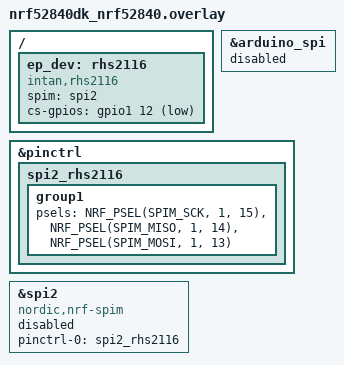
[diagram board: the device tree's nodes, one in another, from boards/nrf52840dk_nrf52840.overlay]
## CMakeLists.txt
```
cmake_minimum_required(VERSION 3.20.0)

# Default `west flash`/`west debug` to the nrfutil runner rather than nrfjprog
# (the legacy nRF Command Line Tools, superseded by nrfutil). Pass `-r <runner>`
# to west to use a different one.
set(BOARD_FLASH_RUNNER nrfutil)

# the RHS2116 driver is an out-of-tree Zephyr module (firmware/modules/rhs2116)
list(APPEND ZEPHYR_EXTRA_MODULES ${CMAKE_CURRENT_SOURCE_DIR}/../modules/rhs2116)

find_package(Zephyr REQUIRED HINTS $ENV{ZEPHYR_BASE})
project(ep_device)

target_include_directories(app PRIVATE src)
target_sources(app PRIVATE
  src/recording.c
  src/stim.c
  src/ble_handler.c
  src/cmd_handler.c
  src/device_info.c
  main/main.c
)

# Zephyr's APP_BUILD_VERSION is only refreshed when the Zephyr repo's index
# changes and never marks uncommitted changes, so generate our own build
# version on every build (see cmake/ep_version.cmake).
set(BUILD_VERSION_H ${CMAKE_CURRENT_BINARY_DIR}/generated/build_version.h)
add_custom_target(ep_build_version
  COMMAND ${CMAKE_COMMAND} -DSRC_DIR=${CMAKE_CURRENT_SOURCE_DIR} -DOUT_FILE=${BUILD_VERSION_H}
          -P ${CMAKE_CURRENT_SOURCE_DIR}/cmake/ep_version.cmake
  BYPRODUCTS ${BUILD_VERSION_H}
)
add_dependencies(app ep_build_version)
target_include_directories(app PRIVATE ${CMAKE_CURRENT_BINARY_DIR}/generated)
```

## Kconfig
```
mainmenu "ep_device"

config EP_DEVICE_HW_REVISION
	int "Hardware (PCB) revision of the ep_device"
	range 0 255
	default 1
	help
	  Reported to the base node by the GET_INFO command. Bump this when
	  building for a new board spin. 0 means a dev kit / breadboard setup.

source "Kconfig.zephyr"
```

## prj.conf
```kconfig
CONFIG_GPIO=y
# the RHS2116 module (firmware/modules/rhs2116) drives SPIM2, TIMER2/3, GPIOTE and
# PPI directly and selects what it needs; NRFX_SPIM2 is only needed for SPIM pinctrl
# support, and is set here because the board's devicetree picks the SPIM
CONFIG_NRFX_SPIM2=y
CONFIG_LOG=y

CONFIG_BT=y
CONFIG_BT_PERIPHERAL=y
CONFIG_BT_ZEPHYR_NUS=y
CONFIG_BT_DEVICE_NAME="mouse"

# Maximum ATT/L2CAP MTU (247 = 251-byte LL data length PDU minus 4-byte
# L2CAP header), backed by matching ACL buffer and controller data length
# sizes so the larger MTU can actually be carried end-to-end.
CONFIG_BT_L2CAP_TX_MTU=247
CONFIG_BT_BUF_ACL_TX_SIZE=251
CONFIG_BT_BUF_ACL_RX_SIZE=251
CONFIG_BT_CTLR_DATA_LENGTH_MAX=251

# Streaming throughput. In Zephyr's controller BT_BUF_ACL_TX_COUNT is also the
# link layer TX queue depth; the default 3 ends each connection event after 3
# packets, leaving the rest of the interval idle. The other counts keep the
# host from becoming the bottleneck instead. recording.c sends with one credit
# per ATT TX buffer (see ble_handler_send_data()).
CONFIG_BT_BUF_ACL_TX_COUNT=16
CONFIG_BT_L2CAP_TX_BUF_COUNT=16
CONFIG_BT_ATT_TX_COUNT=16
CONFIG_BT_CONN_TX_MAX=16

# Connection parameters requested ~5 s after connecting: the default 30-50 ms
# interval (the link test reaches ~1.3 Mbit/s with it), but a 4 s supervision
# timeout like the base node's instead of the default 420 ms, which is easily
# missed under load.
CONFIG_BT_PERIPHERAL_PREF_MIN_INT=24
CONFIG_BT_PERIPHERAL_PREF_MAX_INT=40
CONFIG_BT_PERIPHERAL_PREF_LATENCY=0
CONFIG_BT_PERIPHERAL_PREF_TIMEOUT=400

# report negotiated PHY and data length (logged in ble_handler.c). The USER_*
# options turn the AUTO_* ones off by default, and without AUTO_DATA_LEN_UPDATE
# the host never raises the controller's default TX length from 27 bytes, so
# both are re-enabled explicitly.
CONFIG_BT_USER_PHY_UPDATE=y
CONFIG_BT_USER_DATA_LEN_UPDATE=y
CONFIG_BT_AUTO_PHY_UPDATE=y
CONFIG_BT_AUTO_DATA_LEN_UPDATE=y
```

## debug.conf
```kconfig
# crash hunting: names threads in fault dumps, enables kernel/host asserts and
# gives deferred logging room so a fault dump isn't dropped
#   west build -b <board> ep_device -- -DEXTRA_CONF_FILE="emul.conf;debug.conf"
CONFIG_THREAD_NAME=y
CONFIG_ASSERT=y
CONFIG_LOG_BUFFER_SIZE=4096
```

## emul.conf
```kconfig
# bench testing without the RHS2116 fitted:
#   west build -b <board> ep_device -- -DEXTRA_CONF_FILE=emul.conf
CONFIG_RHS2116_EMUL=y
```

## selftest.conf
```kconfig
# SPI transport self-test at boot (rhs2116_transport_dma_probe() and the stream
# soak in main.c), logged on the console. Takes about a minute.
#   west build -b <board> ep_device -- -DEXTRA_CONF_FILE="emul.conf;debug.conf;selftest.conf"
CONFIG_RHS2116_DMA_PROBE=y
```

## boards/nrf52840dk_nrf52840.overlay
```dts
/*
 * nrf52840dk/nrf52840: the RHS2116 sits on the Arduino header SPI pins
 * (D13/D12/D11 = P1.15/P1.14/P1.13) with CS on D10 (P1.12).
 *
 * the RHS2116 driver drives a SPIM itself (timer/PPI paced streaming). The
 * Arduino header's own bus is spi3, which is avoided because of nRF52840
 * anomaly 198, so spi2 is given the Arduino pins instead and both buses are
 * left disabled for Zephyr's SPI driver.
 */
/ {
    ep_dev: rhs2116 {
        compatible = "intan,rhs2116";
        spim = <&spi2>;
        cs-gpios = <&gpio1 12 GPIO_ACTIVE_LOW>;
    };
};

&arduino_spi {
    status = "disabled";
};

&pinctrl {
    spi2_rhs2116: spi2_rhs2116 {
        group1 {
            psels = <NRF_PSEL(SPIM_SCK, 1, 15)>,
                <NRF_PSEL(SPIM_MISO, 1, 14)>,
                <NRF_PSEL(SPIM_MOSI, 1, 13)>;
        };
    };
};

&spi2 {
    compatible = "nordic,nrf-spim";
    status = "disabled";
    pinctrl-0 = <&spi2_rhs2116>;
    pinctrl-names = "default";
    /delete-property/ pinctrl-1;
};
```

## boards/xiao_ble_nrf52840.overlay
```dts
/*
 * xiao_ble/nrf52840 (base, non-sense):
 * use P0.05 currently for testing with rev1 pcb
 * this corresponds to D5 header on the xiao
 *
 * the RHS2116 driver drives SPIM2 itself (timer/PPI paced streaming), so spi2
 * is left disabled for Zephyr's SPI driver and only its pinctrl (the board's
 * D8/D9/D10 SCK/MISO/MOSI) is used.
 */
/ {
    ep_dev: rhs2116 {
        compatible = "intan,rhs2116";
        spim = <&spi2>;
        cs-gpios = <&gpio0 5 GPIO_ACTIVE_LOW>;
    };
};

&spi2 {
    compatible = "nordic,nrf-spim";
    status = "disabled";
};

// set i2c1 to disabled so that we can use D5 for intan CS line
&i2c1 {
	status = "disabled";
};
```

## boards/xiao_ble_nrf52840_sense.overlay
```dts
/*
 * xiao_ble/nrf52840/sense: the RHS2116 sits on the XIAO expansion header's SPI
 * pins (D8/D9/D10, spi2's pinctrl) with CS on P0.10.
 *
 * the RHS2116 driver drives SPIM2 itself (timer/PPI paced streaming), so spi2
 * is left disabled for Zephyr's SPI driver and only its pinctrl is used.
 */
/ {
    ep_dev: rhs2116 {
        compatible = "intan,rhs2116";
        spim = <&spi2>;
        cs-gpios = <&gpio0 10 GPIO_ACTIVE_LOW>;
    };
};

&spi2 {
    compatible = "nordic,nrf-spim";
    status = "disabled";
};
```

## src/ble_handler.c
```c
#include <zephyr/kernel.h>
#include <zephyr/logging/log.h>

#include <zephyr/bluetooth/bluetooth.h>
#include <zephyr/bluetooth/conn.h>
#include <zephyr/bluetooth/gatt.h>
#include <zephyr/bluetooth/services/nus.h>
#include <zephyr/sys/atomic.h>
#include <zephyr/sys/byteorder.h>

#include "ble_handler.h"

LOG_MODULE_REGISTER(ble_handler, CONFIG_LOG_DEFAULT_LEVEL);

#define DEVICE_NAME     CONFIG_BT_DEVICE_NAME
#define DEVICE_NAME_LEN (sizeof(DEVICE_NAME) - 1)

#define LINK_TEST_STACK     1024
#define LINK_TEST_PRIORITY  8 // below the command thread so STOP is always handled

static const struct ble_handler_cb *app_cb;

// the active connection (ref held), guarded by conn_lock
static struct bt_conn *current_conn;
static struct k_spinlock conn_lock;

static atomic_t link_test_running;
static K_SEM_DEFINE(link_test_sem, 0, 1);

// payload throughput of the last completed link test, 0 if none has run
static atomic_t link_test_last_bps;

/* Credits for data notifications in flight: one per ATT TX buffer, returned by
 * the notify completion callback. Waiting on these instead of retrying
 * bt_gatt_notify() until it stops failing keeps the sender off the host's
 * allocation failure path. Completion callbacks can be skipped when the link
 * drops, so the credits are refilled on every connection. */
#define DATA_TX_CREDITS CONFIG_BT_ATT_TX_COUNT
static K_SEM_DEFINE(data_tx_credits, DATA_TX_CREDITS, DATA_TX_CREDITS);

static const struct bt_data ad[] = {
    BT_DATA_BYTES(BT_DATA_FLAGS, (BT_LE_AD_GENERAL | BT_LE_AD_NO_BREDR)),
    BT_DATA(BT_DATA_NAME_COMPLETE, DEVICE_NAME, DEVICE_NAME_LEN),
};

static const struct bt_data sd[] = {
    BT_DATA_BYTES(BT_DATA_UUID128_ALL, BT_UUID_NUS_SRV_VAL),
};

// -- NEURAL DATA SERVICE --

/* Notify-only characteristic carrying the sample stream (and link test
 * packets), so NUS is left for commands and their replies. The UUIDs are
 * mirrored in base_node/src/ble_central.c; keep the two in sync. */
#define BT_UUID_DATA_SRV_VAL  BT_UUID_128_ENCODE(0xa3c10000, 0x5f2e, 0x4b8a, 0x9d61, 0x7e4f0c2b9a10)
#define BT_UUID_DATA_CHAR_VAL BT_UUID_128_ENCODE(0xa3c10001, 0x5f2e, 0x4b8a, 0x9d61, 0x7e4f0c2b9a10)

static void data_ccc_changed(const struct bt_gatt_attr *attr, uint16_t value) {
    ARG_UNUSED(attr);
    LOG_INF("data notifications %s", value == BT_GATT_CCC_NOTIFY ? "enabled" : "disabled");
}

BT_GATT_SERVICE_DEFINE(data_svc,
    BT_GATT_PRIMARY_SERVICE(BT_UUID_DECLARE_128(BT_UUID_DATA_SRV_VAL)),
    BT_GATT_CHARACTERISTIC(BT_UUID_DECLARE_128(BT_UUID_DATA_CHAR_VAL),
                           BT_GATT_CHRC_NOTIFY, BT_GATT_PERM_NONE, NULL, NULL, NULL),
    BT_GATT_CCC(data_ccc_changed, BT_GATT_PERM_READ | BT_GATT_PERM_WRITE),
    BT_GATT_CUD("Neural Data", BT_GATT_PERM_READ),
);

// the characteristic declaration; bt_gatt_notify() resolves its value handle
#define DATA_CHAR_ATTR (&data_svc.attrs[1])

static void connected(struct bt_conn *conn, uint8_t err) {
    if (err) {
        LOG_ERR("BLE connection failed: %u", err);
        return;
    }
    LOG_INF("BLE connected");

    k_spinlock_key_t key = k_spin_lock(&conn_lock);
    current_conn = bt_conn_ref(conn);
    k_spin_unlock(&conn_lock, key);

    k_sem_reset(&data_tx_credits);
    for (int i = 0; i < DATA_TX_CREDITS; i++) {
        k_sem_give(&data_tx_credits);
    }

    if (app_cb && app_cb->connected) {
        app_cb->connected();
    }
}

static void adv_restart_work_handler(struct k_work *work) {
    ARG_UNUSED(work);

    int ret = bt_le_adv_start(BT_LE_ADV_CONN_ONE_TIME, ad, ARRAY_SIZE(ad), sd, ARRAY_SIZE(sd));
    if (ret) {
        LOG_ERR("Advertising failed to restart: %d", ret);
    } else {
        LOG_INF("BLE advertising restarted");
    }
}

static K_WORK_DEFINE(adv_restart_work, adv_restart_work_handler);

static void disconnected(struct bt_conn *conn, uint8_t reason) {
    LOG_INF("BLE disconnected, reason: %u", reason);

    k_spinlock_key_t key = k_spin_lock(&conn_lock);
    if (current_conn == conn) {
        bt_conn_unref(current_conn);
        current_conn = NULL;
    }
    k_spin_unlock(&conn_lock, key);

    ble_handler_link_test_stop();

    if (app_cb && app_cb->disconnected) {
        app_cb->disconnected();
    }

    // Defer to the system workqueue: the connection object isn't fully
    // released until this callback returns, so advertising can't restart here.
    k_work_submit(&adv_restart_work);
}

// negotiated link parameters, logged to check what the streaming rate can rely on
static void le_param_updated(struct bt_conn *conn, uint16_t interval, uint16_t latency,
                             uint16_t timeout) {
    ARG_UNUSED(conn);
    LOG_INF("conn params: interval %u.%02u ms, latency %u, timeout %u ms",
            interval * 125 / 100, interval * 125 % 100, latency, timeout * 10);
}

static void le_phy_updated(struct bt_conn *conn, struct bt_conn_le_phy_info *param) {
    ARG_UNUSED(conn);
    LOG_INF("PHY: tx %s, rx %s", param->tx_phy == BT_GAP_LE_PHY_2M ? "2M" : "1M/coded",
            param->rx_phy == BT_GAP_LE_PHY_2M ? "2M" : "1M/coded");
}

static void le_data_len_updated(struct bt_conn *conn, struct bt_conn_le_data_len_info *info) {
    ARG_UNUSED(conn);
    LOG_INF("data length: tx %u B / %u us, rx %u B / %u us", info->tx_max_len,
            info->tx_max_time, info->rx_max_len, info->rx_max_time);
}

BT_CONN_CB_DEFINE(conn_callbacks) = {
    .connected = connected,
    .disconnected = disconnected,
    .le_param_updated = le_param_updated,
    .le_phy_updated = le_phy_updated,
    .le_data_len_updated = le_data_len_updated,
};

static void nus_notif_enabled(bool enabled, void *ctx) {
    ARG_UNUSED(ctx);
    LOG_INF("NUS notifications %s", enabled ? "enabled" : "disabled");
}

static void nus_received(struct bt_conn *conn, const void *data, uint16_t len, void *ctx) {
    ARG_UNUSED(conn);
    ARG_UNUSED(ctx);
    LOG_HEXDUMP_DBG(data, len, "NUS RX");

    if (app_cb && app_cb->received) {
        app_cb->received(data, len);
    }
}

static struct bt_nus_cb nus_callbacks = {
    .notif_enabled = nus_notif_enabled,
    .received = nus_received,
};

int ble_handler_init(const struct ble_handler_cb *cb) {
    app_cb = cb;

    int ret = bt_nus_cb_register(&nus_callbacks, NULL);
    if (ret) {
        LOG_ERR("Failed to register NUS callbacks: %d", ret);
        return ret;
    }

    ret = bt_enable(NULL);
    if (ret) {
        LOG_ERR("Bluetooth init failed: %d", ret);
        return ret;
    }

    ret = bt_le_adv_start(BT_LE_ADV_CONN_ONE_TIME, ad, ARRAY_SIZE(ad), sd, ARRAY_SIZE(sd));
    if (ret) {
        LOG_ERR("Advertising failed to start: %d", ret);
        return ret;
    }

    LOG_INF("BLE advertising started as \"%s\"", DEVICE_NAME);
    return 0;
}

int ble_handler_send(const void *data, uint16_t len) {
    return bt_nus_send(NULL, data, len);
}

// returns a new ref to the active connection, or NULL; caller must bt_conn_unref()
static struct bt_conn *get_conn(void) {
    struct bt_conn *conn = NULL;

    k_spinlock_key_t key = k_spin_lock(&conn_lock);
    if (current_conn) {
        conn = bt_conn_ref(current_conn);
    }
    k_spin_unlock(&conn_lock, key);

    return conn;
}

static void data_sent(struct bt_conn *conn, void *user_data) {
    ARG_UNUSED(conn);
    ARG_UNUSED(user_data);
    k_sem_give(&data_tx_credits);
}

int ble_handler_send_data(const void *data, uint16_t len, k_timeout_t timeout) {
    if (k_sem_take(&data_tx_credits, timeout) != 0) {
        return -EAGAIN;
    }

    struct bt_conn *conn = get_conn();
    if (conn == NULL) {
        k_sem_give(&data_tx_credits);
        return -ENOTCONN;
    }

    struct bt_gatt_notify_params params = {
        .attr = DATA_CHAR_ATTR,
        .data = data,
        .len = len,
        .func = data_sent,
    };
    int ret = bt_gatt_notify_cb(conn, &params);
    if (ret) {
        k_sem_give(&data_tx_credits);
    }
    bt_conn_unref(conn);
    return ret;
}

uint16_t ble_handler_data_payload_max(void) {
    struct bt_conn *conn = get_conn();
    if (conn == NULL) {
        return 0;
    }
    uint16_t len = bt_gatt_get_mtu(conn) - 3; // ATT notify header
    bt_conn_unref(conn);
    return MIN(len, CONFIG_BT_L2CAP_TX_MTU - 3);
}

uint32_t ble_handler_link_test_last_bps(void) {
    return (uint32_t)atomic_get(&link_test_last_bps);
}

// -- BLE LINK TEST --

/* Sends full-size data notifications back to back. Each packet starts with a
 * little-endian u32 sequence number (so the receiver can count drops) followed
 * by a fixed byte pattern. bt_gatt_notify() blocks while the TX buffers are full,
 * so this runs at whatever rate the link can sustain. */
static void link_test_thread(void *p1, void *p2, void *p3) {
    ARG_UNUSED(p1);
    ARG_UNUSED(p2);
    ARG_UNUSED(p3);

    static uint8_t buf[CONFIG_BT_L2CAP_TX_MTU - 3]; // ATT MTU minus the notify header

    for (size_t i = 0; i < sizeof(buf); i++) {
        buf[i] = (uint8_t)i;
    }

    while (1) {
        k_sem_take(&link_test_sem, K_FOREVER);

        struct bt_conn *conn = get_conn();
        if (conn == NULL) {
            LOG_WRN("link test: not connected");
            atomic_clear(&link_test_running);
            continue;
        }

        // the negotiated MTU may be smaller than the configured maximum
        uint16_t len = MIN(bt_gatt_get_mtu(conn) - 3, sizeof(buf));
        uint32_t seq = 0;
        uint64_t bytes = 0;
        int64_t start = k_uptime_get();

        LOG_INF("link test started, %u byte packets", len);

        while (atomic_get(&link_test_running)) {
            sys_put_le32(seq, buf);

            int ret = bt_gatt_notify(conn, DATA_CHAR_ATTR, buf, len);
            if (ret == -EAGAIN || ret == -ENOMEM) {
                k_yield();
                continue;
            }
            if (ret) {
                /* e.g. -ENOTCONN on disconnect (the base restarts the test on
                 * reconnect) or -EINVAL if the peer isn't subscribed */
                LOG_ERR("link test: send failed: %d", ret);
                atomic_clear(&link_test_running);
                break;
            }
            seq++;
            bytes += len;
        }

        /* Don't clear link_test_running here: a stop followed quickly by a new
         * start would otherwise be undone. A pending start re-runs the loop via
         * link_test_sem. */
        bt_conn_unref(conn);

        int64_t elapsed_ms = MAX(k_uptime_get() - start, 1);
        atomic_set(&link_test_last_bps, (atomic_val_t)(bytes * 1000 / elapsed_ms));
        LOG_INF("link test stopped: %u packets, %llu bytes in %lld ms (%llu B/s)",
                seq, bytes, elapsed_ms, bytes * 1000 / elapsed_ms);
    }
}

K_THREAD_DEFINE(link_test_tid, LINK_TEST_STACK, link_test_thread, NULL, NULL, NULL,
                LINK_TEST_PRIORITY, 0, 0);

int ble_handler_link_test_start(void) {
    if (atomic_set(&link_test_running, 1)) {
        return -EALREADY;
    }
    k_sem_give(&link_test_sem);
    return 0;
}

void ble_handler_link_test_stop(void) {
    atomic_clear(&link_test_running);
}
```

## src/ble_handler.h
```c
#ifndef BLE_HANDLER_H
#define BLE_HANDLER_H

#include <stdint.h>

#include <zephyr/kernel.h>

/* Application hooks invoked from the BLE stack's context on link changes. */
struct ble_handler_cb {
    void (*connected)(void);
    void (*disconnected)(void);
    /* Data written by the peer to NUS RX. Runs on the BLE RX thread, so it
     * must not block. */
    void (*received)(const uint8_t *data, uint16_t len);
};

/* Registers NUS callbacks, enables Bluetooth and starts advertising.
 * cb may be NULL; the pointed-to struct must outlive the BLE stack. */
int ble_handler_init(const struct ble_handler_cb *cb);

/* Sends data over NUS to all connected peers; used for command replies.
 * Returns bt_nus_send()'s result (-ENOTCONN when nothing is connected, -EAGAIN
 * when TX buffers are full). */
int ble_handler_send(const void *data, uint16_t len);

/* Notifies data on the neural data characteristic to the connected peer.
 * Waits up to timeout for one of the CONFIG_BT_ATT_TX_COUNT notification
 * credits, which come back as the controller finishes sending earlier ones.
 * Returns -EAGAIN if none came back in time, -ENOTCONN when not connected,
 * -EINVAL if the peer isn't subscribed, or another bt_gatt_notify_cb() error. */
int ble_handler_send_data(const void *data, uint16_t len, k_timeout_t timeout);

/* Largest notification payload on the data characteristic for the current
 * connection (negotiated ATT MTU minus the notify header), or 0 if not connected. */
uint16_t ble_handler_data_payload_max(void);

/* Payload bytes/s achieved by the last completed link test, 0 if none has run. */
uint32_t ble_handler_link_test_last_bps(void);

/* Starts streaming full-size data characteristic packets of dummy data (u32 LE sequence number
 * then a byte pattern) as fast as the link allows, on its own thread.
 * Returns -EALREADY if a test is already running. */
int ble_handler_link_test_start(void);

/* Stops the link test; also called automatically on disconnect. */
void ble_handler_link_test_stop(void);

#endif /* BLE_HANDLER_H */
```

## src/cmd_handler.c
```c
#include <errno.h>
#include <string.h>

#include <zephyr/device.h>
#include <zephyr/devicetree.h>
#include <zephyr/kernel.h>
#include <zephyr/logging/log.h>
#include <zephyr/sys/byteorder.h>
#include <zephyr/sys/util.h>

#include "ble_handler.h"
#include "cmd_handler.h"
#include "device_info.h"
#include "recording.h"
#include "stim.h"

LOG_MODULE_REGISTER(cmd_handler, CONFIG_LOG_DEFAULT_LEVEL);

#define CMD_QUEUE_DEPTH      4
#define CMD_THREAD_STACK     2048
#define CMD_THREAD_PRIORITY  7

struct cmd_packet {
    uint16_t len;
    uint8_t data[CMD_MAX_LEN];
};

K_MSGQ_DEFINE(cmd_msgq, sizeof(struct cmd_packet), CMD_QUEUE_DEPTH, 4);

/* Handlers run on the command thread (not the BLE stack), so they may block,
 * e.g. on SPI transfers to the RHS2116. Return 0 on success or a negative errno. */
typedef int (*cmd_fn_t)(const uint8_t *payload, uint16_t len);

struct cmd_entry {
    uint8_t opcode;
    const char *name;
    uint16_t min_len; /* payload bytes, excluding the opcode */
    uint16_t max_len;
    cmd_fn_t fn;
};

static const struct device *const rhs2116_dev = DEVICE_DT_GET(DT_NODELABEL(ep_dev));

// -- COMMAND HANDLERS --

// sends [opcode][status][body...] over NUS
static int reply(uint8_t opcode, int status, const uint8_t *body, uint16_t body_len) {
    uint8_t buf[2 + 48];

    __ASSERT_NO_MSG(body_len <= sizeof(buf) - 2);
    buf[0] = opcode;
    buf[1] = (uint8_t)(int8_t)status;
    if (body_len) {
        memcpy(&buf[2], body, body_len);
    }
    (void)ble_handler_send(buf, body_len + 2);
    return status;
}

static int handle_ping(const uint8_t *payload, uint16_t len) {
    ARG_UNUSED(payload);
    ARG_UNUSED(len);
    LOG_INF("ping");
    return 0;
}

static int handle_get_info(const uint8_t *payload, uint16_t len) {
    ARG_UNUSED(payload);
    ARG_UNUSED(len);

    uint8_t reply[CMD_MAX_LEN];
    reply[0] = CMD_GET_INFO;

    int ret = device_info_encode(&reply[1], sizeof(reply) - 1);
    if (ret < 0) {
        return ret;
    }
    return ble_handler_send(reply, ret + 1);
}

static int handle_start_recording(const uint8_t *payload, uint16_t len) {
    ARG_UNUSED(len);

    struct rec_params params = {
        .chan_mask = sys_get_le16(&payload[0]),
        .rate_hz = sys_get_le32(&payload[2]),
        .bits = payload[6],
    };
    struct rec_info info;

    int ret = recording_start(rhs2116_dev, &params, &info);

    uint8_t body[22];
    body[0] = info.reject;
    sys_put_le32(info.rate_mhz, &body[1]);
    sys_put_le16((uint16_t)info.slot_ticks, &body[5]);
    body[7] = info.slots_per_frame;
    body[8] = info.frames_per_packet;
    sys_put_le32(info.required_bps, &body[9]);
    sys_put_le32(info.link_bps, &body[13]);
    sys_put_le32(info.max_rate_hz, &body[17]);
    return reply(CMD_START_RECORDING, ret, body, 21);
}

static int handle_stop_recording(const uint8_t *payload, uint16_t len) {
    ARG_UNUSED(payload);
    ARG_UNUSED(len);

    // stimulation is timed by the stream, so it has to wind down first
    stim_stop();
    recording_stop();
    return reply(CMD_STOP_RECORDING, 0, NULL, 0);
}

static int handle_start_stimulation(const uint8_t *payload, uint16_t len) {
    ARG_UNUSED(payload);
    ARG_UNUSED(len);

    enum stim_reject why;
    int ret = stim_start(rhs2116_dev, &why);
    uint8_t body[1] = { why };
    return reply(CMD_START_STIMULATION, ret, body, sizeof(body));
}

static int handle_stop_stimulation(const uint8_t *payload, uint16_t len) {
    ARG_UNUSED(payload);
    ARG_UNUSED(len);

    stim_stop();
    return reply(CMD_STOP_STIMULATION, 0, NULL, 0);
}

static int handle_stim_load_biphasic(const uint8_t *payload, uint16_t len) {
    ARG_UNUSED(len);

    struct stim_biphasic b = {
        .chan_mask = sys_get_le16(&payload[0]),
        .neg_mag = payload[2],
        .pos_mag = payload[3],
        .flags = payload[4],
        .phase1_us = sys_get_le16(&payload[5]),
        .interphase_us = sys_get_le16(&payload[7]),
        .phase2_us = sys_get_le16(&payload[9]),
        .recovery_us = sys_get_le16(&payload[11]),
        .period_us = sys_get_le32(&payload[13]),
        .count = sys_get_le16(&payload[17]),
    };
    struct stim_biphasic_frames f = {0};
    enum stim_reject why;

    int ret = stim_load_biphasic(&b, &f, &why);

    uint8_t body[13];
    body[0] = why;
    sys_put_le16(f.phase1, &body[1]);
    sys_put_le16(f.interphase, &body[3]);
    sys_put_le16(f.phase2, &body[5]);
    sys_put_le16(f.recovery, &body[7]);
    sys_put_le32(f.period, &body[9]);
    return reply(CMD_STIM_LOAD_BIPHASIC, ret, body, sizeof(body));
}

#define STIM_EVENTS_HDR_LEN 14

static int handle_stim_load_events(const uint8_t *payload, uint16_t len) {
    struct stim_program p = {
        .chan_mask = sys_get_le16(&payload[0]),
        .neg_mag = payload[2],
        .pos_mag = payload[3],
        .flags = payload[4],
        .period_frames = sys_get_le32(&payload[5]),
        .count = sys_get_le16(&payload[9]),
        .recovery_frames = sys_get_le16(&payload[11]),
        .n_events = payload[13],
    };
    enum stim_reject why = STIM_BAD_EVENTS;
    int ret = -EINVAL;

    if (p.n_events <= STIM_MAX_EVENTS &&
        len == STIM_EVENTS_HDR_LEN + p.n_events * CMD_STIM_EVENT_LEN) {
        const uint8_t *e = &payload[STIM_EVENTS_HDR_LEN];
        for (uint8_t i = 0; i < p.n_events; i++, e += CMD_STIM_EVENT_LEN) {
            p.events[i] = (struct stim_event){
                .frame = sys_get_le32(&e[0]),
                .on = sys_get_le16(&e[4]),
                .pol = sys_get_le16(&e[6]),
                .n_extra = e[8],
                .extra = {
                    { .reg = e[9], .val = sys_get_le16(&e[10]) },
                    { .reg = e[12], .val = sys_get_le16(&e[13]) },
                },
            };
        }
        ret = stim_load_program(&p, &why);
    }

    uint8_t body[1] = { why };
    return reply(CMD_STIM_LOAD_EVENTS, ret, body, sizeof(body));
}

static int handle_get_recording_stats(const uint8_t *payload, uint16_t len) {
    ARG_UNUSED(payload);
    ARG_UNUSED(len);

    struct rec_stats st;
    recording_get_stats(&st);

    uint8_t body[38];
    body[0] = recording_active();
    body[1] = stim_running();
    sys_put_le32(st.stream.frames, &body[2]);
    sys_put_le32(st.stream.blocks, &body[6]);
    sys_put_le32(st.stream.spi_errors, &body[10]);
    sys_put_le32(st.stream.compliance_events, &body[14]);
    sys_put_le32(st.stream.transport.rewinds, &body[18]);
    sys_put_le32(st.stream.transport.late_rewinds, &body[22]);
    sys_put_le32(st.stream.transport.max_guard_used, &body[26]);
    sys_put_le32(st.packets_sent, &body[30]);
    sys_put_le32(st.packets_dropped, &body[34]);
    return reply(CMD_GET_RECORDING_STATS, 0, body, sizeof(body));
}

// payload: u16 channel mask, bit n == RHS2116 channel n
static int handle_set_electrode_mask(const uint8_t *payload, uint16_t len) {
    ARG_UNUSED(len);
    uint16_t mask = sys_get_le16(payload);

    LOG_INF("electrode mask 0x%04x", mask);
    // TODO: store the mask and apply it to the recording/stim channel selection
    return 0;
}

static int handle_start_ble_link_test(const uint8_t *payload, uint16_t len) {
    ARG_UNUSED(payload);
    ARG_UNUSED(len);
    return ble_handler_link_test_start();
}

static int handle_stop_ble_link_test(const uint8_t *payload, uint16_t len) {
    ARG_UNUSED(payload);
    ARG_UNUSED(len);
    ble_handler_link_test_stop();
    return 0;
}

// -- DISPATCH --

/* Add new commands here: an opcode in cmd_handler.h, a handler above, and an
 * entry below giving the accepted payload length range. */
static const struct cmd_entry cmd_table[] = {
    { CMD_PING,               "PING",               0, 0, handle_ping },
    { CMD_GET_INFO,           "GET_INFO",           0, 0, handle_get_info },
    { CMD_START_RECORDING,    "START_RECORDING",    7, 7, handle_start_recording },
    { CMD_STOP_RECORDING,     "STOP_RECORDING",     0, 0, handle_stop_recording },
    { CMD_START_STIMULATION,  "START_STIMULATION",  0, 0, handle_start_stimulation },
    { CMD_STOP_STIMULATION,   "STOP_STIMULATION",   0, 0, handle_stop_stimulation },
    { CMD_STIM_LOAD_BIPHASIC, "STIM_LOAD_BIPHASIC", 19, 19, handle_stim_load_biphasic },
    { CMD_STIM_LOAD_EVENTS,   "STIM_LOAD_EVENTS",   STIM_EVENTS_HDR_LEN,
      STIM_EVENTS_HDR_LEN + STIM_MAX_EVENTS * CMD_STIM_EVENT_LEN, handle_stim_load_events },
    { CMD_GET_RECORDING_STATS, "GET_RECORDING_STATS", 0, 0, handle_get_recording_stats },
    { CMD_SET_ELECTRODE_MASK, "SET_ELECTRODE_MASK", 2, 2, handle_set_electrode_mask },
    { CMD_START_BLE_LINK_TEST, "START_BLE_LINK_TEST", 0, 0, handle_start_ble_link_test },
    { CMD_STOP_BLE_LINK_TEST,  "STOP_BLE_LINK_TEST",  0, 0, handle_stop_ble_link_test },
};

static const struct cmd_entry *find_cmd(uint8_t opcode) {
    for (size_t i = 0; i < ARRAY_SIZE(cmd_table); i++) {
        if (cmd_table[i].opcode == opcode) {
            return &cmd_table[i];
        }
    }
    return NULL;
}

static void dispatch(const struct cmd_packet *pkt) {
    uint8_t opcode = pkt->data[0];
    const uint8_t *payload = &pkt->data[1];
    uint16_t payload_len = pkt->len - 1;

    const struct cmd_entry *cmd = find_cmd(opcode);
    if (cmd == NULL) {
        LOG_WRN("unknown opcode 0x%02x (%u byte payload)", opcode, payload_len);
        return;
    }

    if (payload_len < cmd->min_len || payload_len > cmd->max_len) {
        LOG_WRN("%s: bad payload length %u (expected %u..%u)",
                cmd->name, payload_len, cmd->min_len, cmd->max_len);
        return;
    }

    int ret = cmd->fn(payload, payload_len);
    if (ret < 0) {
        LOG_ERR("%s failed: %d", cmd->name, ret);
    } else {
        LOG_DBG("%s ok", cmd->name);
    }
}

static void cmd_thread(void *p1, void *p2, void *p3) {
    ARG_UNUSED(p1);
    ARG_UNUSED(p2);
    ARG_UNUSED(p3);

    struct cmd_packet pkt;

    while (1) {
        k_msgq_get(&cmd_msgq, &pkt, K_FOREVER);
        dispatch(&pkt);
    }
}

K_THREAD_DEFINE(cmd_tid, CMD_THREAD_STACK, cmd_thread, NULL, NULL, NULL,
                CMD_THREAD_PRIORITY, 0, 0);

int cmd_handler_submit(const uint8_t *data, uint16_t len) {
    if (len == 0 || len > CMD_MAX_LEN) {
        LOG_WRN("dropping command of length %u", len);
        return -EINVAL;
    }

    struct cmd_packet pkt = { .len = len };
    memcpy(pkt.data, data, len);

    // never block here: this is called from the BLE RX thread
    int ret = k_msgq_put(&cmd_msgq, &pkt, K_NO_WAIT);
    if (ret) {
        LOG_WRN("command queue full, dropping opcode 0x%02x", data[0]);
        return -ENOMEM;
    }
    return 0;
}

void cmd_handler_stop_all(void) {
    uint8_t stop = CMD_STOP_RECORDING;
    (void)cmd_handler_submit(&stop, 1);
}
```

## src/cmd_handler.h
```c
#ifndef CMD_HANDLER_H
#define CMD_HANDLER_H

#include <stdint.h>

/*
 * Command packet format (base node -> ep_device, over NUS RX):
 *
 *   byte 0      opcode   (enum cmd_opcode)
 *   byte 1..n   payload  (opcode specific, multi-byte fields little-endian)
 *
 * One NUS write carries exactly one command. The payload length is whatever
 * follows the opcode, and is checked against the opcode's table entry in
 * cmd_handler.c before the handler runs.
 *
 * Commands that return data reply over NUS TX with the same layout:
 * [opcode of the command][payload...].
 */

/* Largest command accepted: one ATT MTU (247) minus the 3-byte ATT header. */
#define CMD_MAX_LEN 244

enum cmd_opcode {
    CMD_PING               = 0x01,
    CMD_GET_INFO           = 0x02, /* replies with device_info.h's payload */

    /* recording / stimulation control, payloads and replies below */
    CMD_START_RECORDING    = 0x10,
    CMD_STOP_RECORDING     = 0x11,
    CMD_START_STIMULATION  = 0x12,
    CMD_STOP_STIMULATION   = 0x13,
    CMD_STIM_LOAD_BIPHASIC = 0x14,
    CMD_STIM_LOAD_EVENTS   = 0x15,
    CMD_GET_RECORDING_STATS = 0x16,

    /* electrode setup / parameters */
    CMD_SET_ELECTRODE_MASK = 0x20,

    /* diagnostics */
    CMD_START_BLE_LINK_TEST = 0x30,
    CMD_STOP_BLE_LINK_TEST  = 0x31,
};

/*
 * Recording / stimulation payloads (all little-endian). Every one of these
 * commands replies [opcode][status s8 (0 or -errno)]... as listed.
 *
 * START_RECORDING   payload: chan_mask u16, rate_hz u32, bits u8
 *                   reply:   status, reject u8 (enum rec_reject), rate_mhz u32,
 *                            slot_ticks u16, slots_per_frame u8, frames_per_packet u8,
 *                            required_bps u32, link_bps u32, max_rate_hz u32
 * STOP_RECORDING    reply:   status (also stops any stimulation first)
 * START_STIMULATION reply:   status, reject u8 (enum stim_reject)
 * STOP_STIMULATION  reply:   status
 * STIM_LOAD_BIPHASIC payload: chan_mask u16, neg_mag u8, pos_mag u8, flags u8,
 *                            phase1_us u16, interphase_us u16, phase2_us u16,
 *                            recovery_us u16, period_us u32, count u16
 *                   reply:   status, reject u8, phase1 u16, interphase u16, phase2 u16,
 *                            recovery u16, period u32 (all in frames)
 * STIM_LOAD_EVENTS  payload: chan_mask u16, neg_mag u8, pos_mag u8, flags u8,
 *                            period_frames u32, count u16, recovery_frames u16, n u8,
 *                            then n events of: frame u32, on u16, pol u16, n_extra u8,
 *                            reg u8, val u16, reg u8, val u16
 *                   reply:   status, reject u8
 * GET_RECORDING_STATS reply: status, recording u8, stim u8, frames u32, blocks u32,
 *                            spi_errors u32, compliance_events u32, rewinds u32,
 *                            late_rewinds u32, max_guard_used u32, packets_sent u32,
 *                            packets_dropped u32
 */
#define CMD_STIM_EVENT_LEN 15

/* Queues a received command for processing on the command thread. Safe to call
 * from the BLE RX callback: it only copies the data and never blocks.
 * Returns -EINVAL for empty/oversized packets, -ENOMEM if the queue is full. */
int cmd_handler_submit(const uint8_t *data, uint16_t len);

/* Queues a STOP_RECORDING (which also stops stimulation), e.g. on disconnect. */
void cmd_handler_stop_all(void);

#endif /* CMD_HANDLER_H */
```

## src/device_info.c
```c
#include <errno.h>
#include <string.h>

#include <app_version.h>
#include <build_version.h>
#include <zephyr/kernel.h>
#include <zephyr/version.h>
#include <zephyr/sys/byteorder.h>
#include <zephyr/sys/util.h>

#include "device_info.h"

/* Written once by main() after probing the RHS2116, read by the command thread. */
static struct k_spinlock lock;
static uint8_t rhs2116_state = DEVICE_INFO_RHS2116_UNKNOWN;
static int16_t rhs2116_error;
static uint8_t rhs2116_chip_id;
static uint8_t rhs2116_die_revision;
static uint8_t rhs2116_num_channels;

void device_info_set_rhs2116(uint8_t chip_id, uint8_t die_revision, uint8_t num_channels) {
    k_spinlock_key_t key = k_spin_lock(&lock);
    rhs2116_state = IS_ENABLED(CONFIG_RHS2116_EMUL) ? DEVICE_INFO_RHS2116_EMULATED
                                                    : DEVICE_INFO_RHS2116_OK;
    rhs2116_error = 0;
    rhs2116_chip_id = chip_id;
    rhs2116_die_revision = die_revision;
    rhs2116_num_channels = num_channels;
    k_spin_unlock(&lock, key);
}

void device_info_set_rhs2116_error(int err) {
    k_spinlock_key_t key = k_spin_lock(&lock);
    rhs2116_state = DEVICE_INFO_RHS2116_ERROR;
    rhs2116_error = (int16_t)err;
    k_spin_unlock(&lock, key);
}

// appends [u8 len][bytes], truncating str to 255 bytes
static int put_str(uint8_t *buf, size_t size, size_t *pos, const char *str) {
    size_t len = MIN(strlen(str), UINT8_MAX);

    if (*pos + 1 + len > size) {
        return -ENOMEM;
    }
    buf[(*pos)++] = (uint8_t)len;
    memcpy(&buf[*pos], str, len);
    *pos += len;
    return 0;
}

int device_info_encode(uint8_t *buf, size_t size) {
    if (size < 11) {
        return -ENOMEM;
    }

    buf[0] = DEVICE_INFO_FORMAT;
    buf[1] = APP_VERSION_MAJOR;
    buf[2] = APP_VERSION_MINOR;
    buf[3] = APP_PATCHLEVEL;
    buf[4] = CONFIG_EP_DEVICE_HW_REVISION;

    k_spinlock_key_t key = k_spin_lock(&lock);
    buf[5] = rhs2116_state;
    sys_put_le16((uint16_t)rhs2116_error, &buf[6]);
    buf[8] = rhs2116_chip_id;
    buf[9] = rhs2116_die_revision;
    buf[10] = rhs2116_num_channels;
    k_spin_unlock(&lock, key);

    size_t pos = 11;
    int ret = put_str(buf, size, &pos, CONFIG_BT_DEVICE_NAME);
    if (!ret) {
        ret = put_str(buf, size, &pos, EP_BUILD_VERSION);
    }
    if (!ret) {
        ret = put_str(buf, size, &pos, KERNEL_VERSION_STRING);
    }
    return ret ? ret : (int)pos;
}
```

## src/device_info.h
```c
#ifndef DEVICE_INFO_H
#define DEVICE_INFO_H

#include <stddef.h>
#include <stdint.h>

/*
 * GET_INFO reply payload (ep_device -> base node, sent over NUS TX after the
 * echoed CMD_GET_INFO opcode byte). Mirrors base_node/src/ep_info.c; keep the
 * two in sync and bump DEVICE_INFO_FORMAT on incompatible changes.
 *
 *   byte 0      format version (DEVICE_INFO_FORMAT)
 *   byte 1..3   firmware version major, minor, patch (from ep_device/VERSION)
 *   byte 4      hardware revision (CONFIG_EP_DEVICE_HW_REVISION)
 *   byte 5      RHS2116 state (enum device_info_rhs2116_state)
 *   byte 6..7   RHS2116 error, s16 LE (negative errno, valid in STATE_ERROR)
 *   byte 8      RHS2116 chip ID         \
 *   byte 9      RHS2116 die revision     > valid in STATE_OK only
 *   byte 10     RHS2116 channel count   /
 *   then three length-prefixed strings ([u8 len][bytes], no NUL):
 *               device name, build version (git describe, -dirty if
 *               ep_device has uncommitted changes), Zephyr version
 */
#define DEVICE_INFO_FORMAT 1

enum device_info_rhs2116_state {
    DEVICE_INFO_RHS2116_UNKNOWN = 0, /* not queried yet */
    DEVICE_INFO_RHS2116_OK      = 1,
    DEVICE_INFO_RHS2116_ERROR   = 2, /* query failed, see error field */
    DEVICE_INFO_RHS2116_EMULATED = 3, /* no chip, CONFIG_RHS2116_EMUL; info is the model's */
};

/* Records the read-only info read from the RHS2116 once it has been verified. */
void device_info_set_rhs2116(uint8_t chip_id, uint8_t die_revision, uint8_t num_channels);

/* Records that querying the RHS2116 failed with err (negative errno). */
void device_info_set_rhs2116_error(int err);

/* Encodes the GET_INFO reply payload (format above) into buf.
 * Returns the number of bytes written, or -ENOMEM if buf is too small. */
int device_info_encode(uint8_t *buf, size_t size);

#endif /* DEVICE_INFO_H */
```

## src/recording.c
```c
#include <errno.h>
#include <string.h>

#include <zephyr/kernel.h>
#include <zephyr/logging/log.h>
#include <zephyr/sys/atomic.h>
#include <zephyr/sys/byteorder.h>
#include <zephyr/sys/util.h>

#include "ble_handler.h"
#include "recording.h"
#include <rhs2116/rhs2116_stream.h>

LOG_MODULE_REGISTER(recording, CONFIG_LOG_DEFAULT_LEVEL);

#define PKT_MAX_LEN      (CONFIG_BT_L2CAP_TX_MTU - 3)
#define PKT_POOL_SIZE    24
#define SEND_THREAD_STACK 1024
#define SEND_THREAD_PRIO  5

struct pkt_ref {
    uint8_t *buf;
    uint16_t len;
};

K_MEM_SLAB_DEFINE_STATIC(pkt_slab, PKT_MAX_LEN, PKT_POOL_SIZE, 4);
K_MSGQ_DEFINE(send_q, sizeof(struct pkt_ref), PKT_POOL_SIZE, 4);

static atomic_t active;
static atomic_t stim_active;
static atomic_t dropped_pending; // a drop happened since the last packet went out
static atomic_t seq;
static atomic_t packets_sent;
static atomic_t packets_dropped;
static atomic_ptr_t fault_hook;

// sample packer state, only touched on the stream thread (and by stop once the
// stream thread is done with it)
static struct packer {
    uint8_t bits;
    uint8_t n_ch;
    uint16_t chan_mask;
    uint8_t frames_per_packet;
    uint8_t *buf;
    uint16_t pos;
    uint8_t n_frames;
    uint32_t acc;
    uint8_t acc_bits;
} pk;

static uint8_t next_flags(void) {
    uint8_t flags = atomic_get(&stim_active) ? REC_FLAG_STIM_ACTIVE : 0;
    if (atomic_clear(&dropped_pending)) {
        flags |= REC_FLAG_DROPPED;
    }
    return flags;
}

static void count_drop(void) {
    atomic_inc(&seq);
    atomic_inc(&packets_dropped);
    atomic_set(&dropped_pending, 1);
}

// stamps the common header and queues the packet for the sender thread
static void submit(uint8_t *buf, uint16_t len) {
    buf[1] = next_flags();
    sys_put_le16((uint16_t)atomic_inc(&seq), &buf[2]);

    struct pkt_ref ref = { .buf = buf, .len = len };
    if (k_msgq_put(&send_q, &ref, K_NO_WAIT) != 0) {
        k_mem_slab_free(&pkt_slab, buf);
        atomic_inc(&packets_dropped);
        atomic_set(&dropped_pending, 1);
    }
}

// -- SAMPLE PACKING --

static void pack_finish(void) {
    if (pk.buf == NULL) {
        return;
    }
    if (pk.acc_bits) {
        pk.buf[pk.pos++] = (uint8_t)pk.acc;
    }
    pk.buf[8] = pk.n_frames;
    submit(pk.buf, pk.pos);
    pk.buf = NULL;
}

static void on_frame(uint32_t frame_idx, const uint16_t *samples, uint8_t n_ch) {
    if (pk.buf == NULL) {
        void *mem;
        if (k_mem_slab_alloc(&pkt_slab, &mem, K_NO_WAIT) != 0) {
            // no buffer: drop this packet's worth of frames, leaving a seq gap
            if (frame_idx % pk.frames_per_packet == 0) {
                count_drop();
            }
            return;
        }
        pk.buf = mem;
        pk.buf[0] = REC_PKT_SAMPLES;
        sys_put_le32(frame_idx, &pk.buf[4]);
        pk.buf[9] = pk.bits;
        sys_put_le16(pk.chan_mask, &pk.buf[10]);
        pk.pos = REC_SAMPLES_HDR_LEN;
        pk.n_frames = 0;
        pk.acc = 0;
        pk.acc_bits = 0;
    }

    const uint8_t shift = 16 - pk.bits;
    for (uint8_t k = 0; k < n_ch; k++) {
        pk.acc |= (uint32_t)(samples[k] >> shift) << pk.acc_bits;
        pk.acc_bits += pk.bits;
        while (pk.acc_bits >= 8) {
            pk.buf[pk.pos++] = (uint8_t)pk.acc;
            pk.acc >>= 8;
            pk.acc_bits -= 8;
        }
    }

    if (++pk.n_frames == pk.frames_per_packet) {
        pack_finish();
    }
}

static void on_status(enum rhs2116_stream_status status, uint32_t frame, uint32_t value) {
    switch (status) {
    case RHS2116_STREAM_STATUS_SPI_ERROR:
        recording_event(REC_EVT_SPI_ERROR, frame, (uint16_t)value, (uint16_t)(value >> 16));
        break;
    case RHS2116_STREAM_STATUS_COMPLIANCE:
        recording_event(REC_EVT_COMPLIANCE, frame, (uint16_t)value, 0);
        break;
    case RHS2116_STREAM_STATUS_STOPPED:
        atomic_clear(&active);
        pack_finish();
        recording_event(REC_EVT_STREAM_STOPPED, frame, (uint16_t)value, 0);
        break;
    }

    rec_fault_hook_t hook = (rec_fault_hook_t)atomic_ptr_get(&fault_hook);
    if (hook) {
        hook(status, frame, value);
    }
}

static const struct rhs2116_stream_sink sink = {
    .frame = on_frame,
    .status = on_status,
};

// -- SENDER --

static void send_thread(void *p1, void *p2, void *p3) {
    ARG_UNUSED(p1);
    ARG_UNUSED(p2);
    ARG_UNUSED(p3);

    struct pkt_ref ref;

    while (1) {
        if (k_msgq_get(&send_q, &ref, K_FOREVER) != 0) {
            continue;
        }

        /* Wait for a notification credit. They keep coming back while the link
         * is up, and a lost link ends the wait with -ENOTCONN, so this doesn't
         * spin or log. -ENOMEM shouldn't happen with credits; it's retried too. */
        int ret;
        do {
            ret = ble_handler_send_data(ref.buf, ref.len, K_MSEC(100));
        } while (ret == -EAGAIN || ret == -ENOMEM);

        if (ret == 0) {
            atomic_inc(&packets_sent);
        } else {
            atomic_inc(&packets_dropped);
        }
        k_mem_slab_free(&pkt_slab, ref.buf);
    }
}

K_THREAD_DEFINE(rec_send_tid, SEND_THREAD_STACK, send_thread, NULL, NULL, NULL,
                SEND_THREAD_PRIO, 0, 0);

// -- CONTROL --

static bool bits_valid(uint8_t bits) {
    return bits == 8 || bits == 10 || bits == 12 || bits == 16;
}

int recording_start(const struct device *dev, const struct rec_params *p, struct rec_info *info) {
    uint8_t n_ch = (uint8_t)POPCOUNT(p->chan_mask);

    *info = (struct rec_info){
        .link_bps = ble_handler_link_test_last_bps(),
        .max_rate_hz = rhs2116_stream_max_rate_hz(MAX(n_ch, 1)),
    };

    if (atomic_get(&active)) {
        info->reject = REC_BUSY;
        return -EBUSY;
    }
    if (!bits_valid(p->bits)) {
        info->reject = REC_BAD_BITS;
        return -EINVAL;
    }

    uint16_t payload_max = ble_handler_data_payload_max();
    if (payload_max == 0) {
        payload_max = PKT_MAX_LEN;
    }
    payload_max = MIN(payload_max, PKT_MAX_LEN);

    uint32_t fpp = 0;
    if (n_ch) {
        fpp = (uint32_t)(payload_max - REC_SAMPLES_HDR_LEN) * 8 / (n_ch * p->bits);
        fpp = CLAMP(fpp, 1, UINT8_MAX);
    }

    pk = (struct packer){
        .bits = p->bits,
        .n_ch = n_ch,
        .chan_mask = p->chan_mask,
        .frames_per_packet = (uint8_t)fpp,
    };
    atomic_clear(&seq);
    atomic_clear(&packets_sent);
    atomic_clear(&packets_dropped);
    atomic_clear(&dropped_pending);

    struct rhs2116_stream_layout layout;
    enum rhs2116_stream_reject why;

    // set before the stream thread can deliver its first frame
    atomic_set(&active, 1);
    int ret = rhs2116_stream_start(dev, p->chan_mask, p->rate_hz, &sink, &layout, &why);
    if (ret < 0) {
        atomic_clear(&active);
        info->reject = (enum rec_reject)why;
        return ret;
    }

    uint32_t pkt_len = REC_SAMPLES_HDR_LEN + DIV_ROUND_UP(fpp * n_ch * p->bits, 8);
    info->reject = REC_OK;
    info->rate_mhz = layout.rate_mhz;
    info->slot_ticks = layout.slot_ticks;
    info->slots_per_frame = layout.slots_per_frame;
    info->frames_per_packet = (uint8_t)fpp;
    info->required_bps = (uint32_t)DIV_ROUND_UP((uint64_t)layout.rate_mhz * pkt_len,
                                                1000ull * fpp);

    if (info->link_bps && info->required_bps > info->link_bps) {
        LOG_WRN("recording needs %u B/s but the last link test managed %u B/s",
                info->required_bps, info->link_bps);
    }
    return 0;
}

void recording_stop(void) {
    if (!atomic_get(&active)) {
        return;
    }
    rhs2116_stream_stop();
    // the stream thread is finished with the packer once stop returns
    atomic_clear(&active);
    pack_finish();
}

bool recording_active(void) {
    return atomic_get(&active);
}

void recording_event(enum rec_event_code code, uint32_t frame, uint16_t a, uint16_t b) {
    void *mem;
    if (k_mem_slab_alloc(&pkt_slab, &mem, K_NO_WAIT) != 0) {
        count_drop();
        return;
    }

    uint8_t *buf = mem;
    buf[0] = REC_PKT_EVENT;
    buf[4] = code;
    sys_put_le32(frame, &buf[5]);
    sys_put_le16(a, &buf[9]);
    sys_put_le16(b, &buf[11]);
    submit(buf, REC_EVENT_LEN);
}

void recording_set_stim_active(bool on) {
    atomic_set(&stim_active, on);
}

void recording_set_fault_hook(rec_fault_hook_t hook) {
    atomic_ptr_set(&fault_hook, (atomic_ptr_val_t)hook);
}

void recording_get_stats(struct rec_stats *out) {
    out->packets_sent = atomic_get(&packets_sent);
    out->packets_dropped = atomic_get(&packets_dropped);
    rhs2116_stream_get_stats(&out->stream);
}
```
